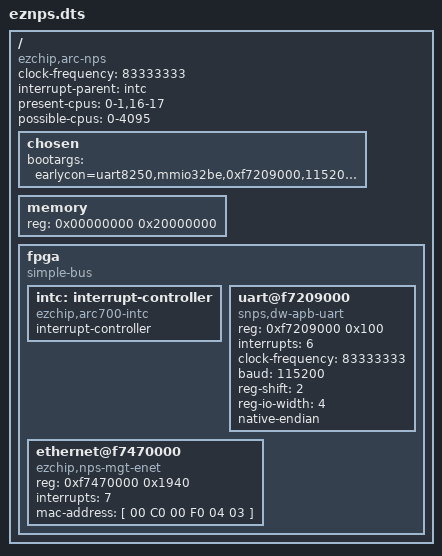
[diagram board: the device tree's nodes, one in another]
/*******************************************************************************

  Copyright(c) 2015 EZchip Technologies.

  This program is free software; you can redistribute it and/or modify it
  under the terms and conditions of the GNU General Public License,
  version 2, as published by the Free Software Foundation.

  This program is distributed in the hope it will be useful, but WITHOUT
  ANY WARRANTY; without even the implied warranty of MERCHANTABILITY or
  FITNESS FOR A PARTICULAR PURPOSE.  See the GNU General Public License for
  more details.

  The full GNU General Public License is included in this distribution in
  the file called "COPYING".

*******************************************************************************/
/dts-v1/;

/include/ "skeleton.dtsi"

/ {
	compatible = "ezchip,arc-nps";
	clock-frequency = <83333333>;	/* 83.333333 MHZ */
	#address-cells = <1>;
	#size-cells = <1>;
	interrupt-parent = <&intc>;
	present-cpus = "0-1,16-17";
	possible-cpus = "0-4095";

	chosen {
		bootargs = "earlycon=uart8250,mmio32be,0xf7209000,115200n8 console=ttyS0,115200n8 rcupdate.rcu_cpu_stall_suppress=1";
	};

	memory {
		device_type = "memory";
		reg = <0x00000000 0x20000000>;	/* 512M */
	};

	fpga {
		compatible = "simple-bus";
		#address-cells = <1>;
		#size-cells = <1>;

		/* child and parent address space 1:1 mapped */
		ranges;

		intc: interrupt-controller {
			compatible = "ezchip,arc700-intc";
			interrupt-controller;
			#interrupt-cells = <1>;
		};

		uart@f7209000 {
			compatible = "snps,dw-apb-uart";
			device_type = "serial";
			reg = <0xf7209000 0x100>;
			interrupts = <6>;
			clock-frequency = <83333333>;
			baud = <115200>;
			reg-shift = <2>;
			reg-io-width = <4>;
			native-endian;
		};

		ethernet@f7470000 {
			compatible = "ezchip,nps-mgt-enet";
			reg = <0xf7470000 0x1940>;
			interrupts = <7>;
			mac-address = [ 00 C0 00 F0 04 03 ];
		};
	};
};
